# STM32WL3Rx register map
File version: 1.0
Registers are 32-bit, read-write, reset 0x0 unless marked. A register's access mark holds for its fields unless they carry their own. Offsets are from the block's base; [hi:lo] are bit positions; {n}, {i} and the like mark numbered series.

## ADC1 — ADC (ADC)
Base 0x41006000
0x00 VERSION_ID — (@ 0x00000000) VERSION_ID register
  [7:0] VERSION_ID
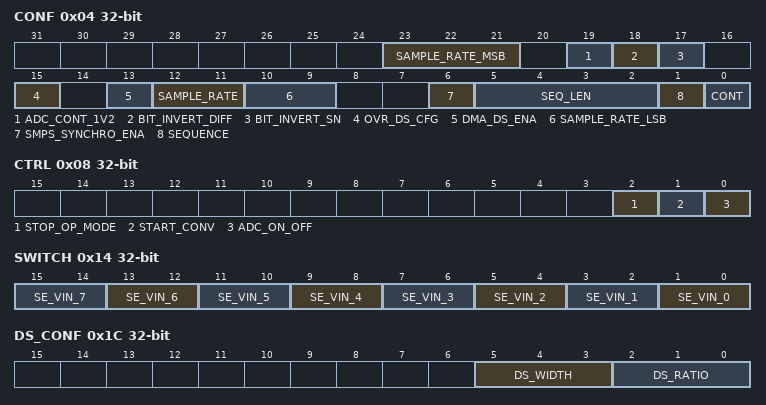
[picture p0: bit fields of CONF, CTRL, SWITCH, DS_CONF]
0x04 CONF — (@ 0x00000004) ADC configuration register
  [23:21] SAMPLE_RATE_MSB
  [19] ADC_CONT_1V2
    0=START; 1=END
  [18] BIT_INVERT_DIFF
  [17] BIT_INVERT_SN
  [15] OVR_DS_CFG
    0=LOST (Previous data is preserved, new data is lost.); 1=KEPT (Previous data is overwritten, new data is kept.)
  [13] DMA_DS_ENA
  [12:11] SAMPLE_RATE
  [10:9] SAMPLE_RATE_LSB
  [6] SMPS_SYNCHRO_ENA
  [5:2] SEQ_LEN
  [1] SEQUENCE
  [0] CONT
0x08 CTRL — (@ 0x00000008) ADC control register
  [2] STOP_OP_MODE, [1] START_CONV, [0] ADC_ON_OFF
0x14 SWITCH — (@ 0x00000014) ADC switch control for Input Selection
  [2n+1:2n] SE_VIN_{n} (n=0..7)
0x1C DS_CONF — (@ 0x0000001C) Downsampler configuration register
  [5:3] DS_WIDTH
  [2:0] DS_RATIO
    0=RATIO_1 (ADC Down Sampler ratio 1, no down sampling (default)); 1=RATIO_2 (ADC Down Sampler ratio 2); 2=RATIO_4 (ADC Down Sampler ratio 4); 3=RATIO_8 (ADC Down Sampler ratio 8); 4=RATIO_16 (ADC Down Sampler ratio 16); 5=RATIO_32 (ADC Down Sampler ratio 32); 6=RATIO_64 (ADC Down Sampler ratio 64); 7=RATIO_128 (ADC Down Sampler ratio 128)
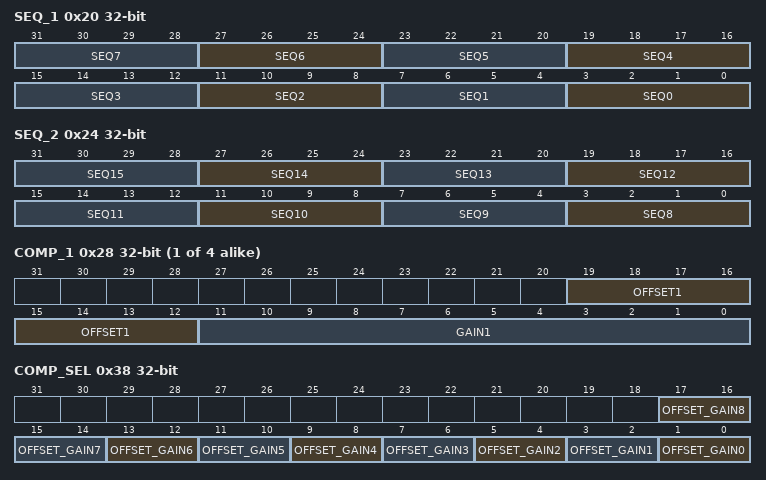
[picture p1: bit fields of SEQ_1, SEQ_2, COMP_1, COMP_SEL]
0x20 SEQ_1 — (@ 0x00000020) ADC regular sequence programming register 1
  [4n+3:4n] SEQ{n} (n=0..7)
0x24 SEQ_2 — (@ 0x00000024) ADC regular sequence programming register 2
  [4n-29:4n-32] SEQ{n} (n=8..15)
{0x24+4i} COMP_{i} (i=1..4) — (@ {0x24+4i}) ADC Gain &
  [19:12] OFFSET{i}, [11:0] GAIN{i}
0x38 COMP_SEL — (@ 0x00000038) ADC Gain &
  [2n+1:2n] OFFSET_GAIN{n} (n=0..8)
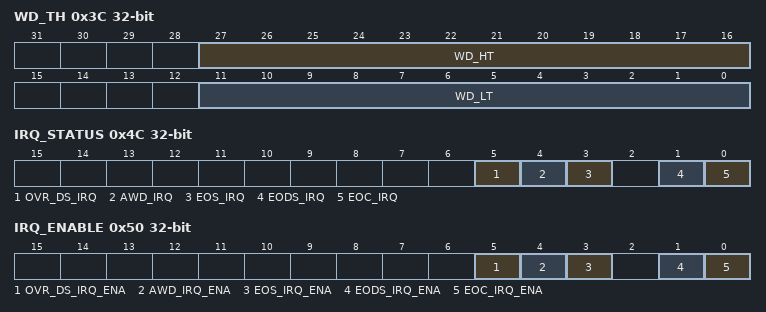
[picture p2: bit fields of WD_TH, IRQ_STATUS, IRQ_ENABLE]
0x3C WD_TH — (@ 0x0000003C) ADC watchdog threshold register register
  [27:16] WD_HT, [11:0] WD_LT
0x40 WD_CONF — (@ 0x00000040) ADC watchdog configuration register
  [15:0] AWD_CHX
    1=VINM0 (ADC watchdog channel selection: VINM0 to negative input); 2=VINM1 (ADC watchdog channel selection: VINM1 to negative input); 4=VINM2 (ADC watchdog channel selection: VINM2 to negative input); 8=VINM3 (ADC watchdog channel selection: VINM3 to negative input); 16=MICROM (ADC watchdog channel selection: MICROM to negative input); 32=VBAT (ADC watchdog channel selection: VBAT to negative input); 64=GND_NEG (ADC watchdog channel selection: GND to negative input); 128=VDDA_NEG (ADC watchdog channel selection: VDDA to negative input); 0x100=VINP0 (ADC watchdog channel selection: VINP0 to positive input); 0x200=VINP1 (ADC watchdog channel selection: VINP1 to positive input); 0x400=VINP2 (ADC watchdog channel selection: VINP2 to positive input); 0x800=VINP3 (ADC watchdog channel selection: VINP3 to positive input); 0x1000=MICROP (ADC watchdog channel selection: MICROP to positive input); 0x2000=TEMPSENSOR (ADC watchdog channel selection: TEMP to positive input); 0x4000=GND_POS (ADC watchdog channel selection: GND to positive input); 0x8000=VDDA_POS (ADC watchdog channel selection: VDDA to positive input)
0x44 DS_DATAOUT — (@ 0x00000044) Downsampler Data output register
  [15:0] DS_DATA
0x4C IRQ_STATUS — (@ 0x0000004C) Interrupt Status register
  [5] OVR_DS_IRQ, [4] AWD_IRQ, [3] EOS_IRQ, [1] EODS_IRQ, [0] EOC_IRQ
0x50 IRQ_ENABLE — (@ 0x00000050) Enable/disable Interrupts
  [5] OVR_DS_IRQ_ENA, [4] AWD_IRQ_ENA, [3] EOS_IRQ_ENA, [1] EODS_IRQ_ENA, [0] EOC_IRQ_ENA

## SPI3 — Serial peripheral interface/Inter-IC sound (SPI)
Base 0x41007000
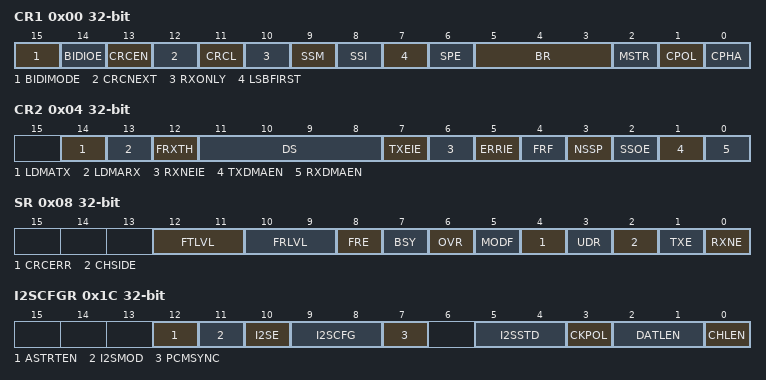
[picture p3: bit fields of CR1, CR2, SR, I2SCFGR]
0x00 CR1 — (@ 0x00000000) Control register 1
  [15] BIDIMODE
  [14] BIDIOE
  [13] CRCEN
  [12] CRCNEXT
  [11] CRCL
    0=CRC_8BIT (8-bit CRC length); 1=CRC_16BIT (16-bit CRC length)
  [10] RXONLY
  [9] SSM
  [8] SSI
  [7] LSBFIRST
    1=LSB_FIRST (Data is transmitted/received with the LSB first); 0=MSB_FIRST (Data is transmitted/received with the MSB first)
  [6] SPE
  [5:3] BR
    0=DIV2 (BaudRate control equal to fPCLK/2); 1=DIV4 (BaudRate control equal to fPCLK/4); 2=DIV8 (BaudRate control equal to fPCLK/8); 3=DIV16 (BaudRate control equal to fPCLK/16); 4=DIV32 (BaudRate control equal to fPCLK/32); 5=DIV64 (BaudRate control equal to fPCLK/64); 6=DIV128 (BaudRate control equal to fPCLK/128); 7=DIV256 (BaudRate control equal to fPCLK/256)
  [2] MSTR
  [1] CPOL
    0=LOW (Clock to 0 when idle); 1=HIGH (Clock to 1 when idle)
  [0] CPHA
    0=PHASE_1EDGE (First clock transition is the first data capture edge); 1=PHASE_2EDGE (Second clock transition is the first data capture edge)
0x04 CR2 — (@ 0x00000004) Control register 2
  [14] LDMATX
  [13] LDMARX
  [12] FRXTH
    0=HALF (RXNE event is generated if FIFO level is greater than or equal to 1/2 (16-bit)); 1=QUARTER (RXNE event is generated if FIFO level is greater than or equal to 1/4 (8-bit))
  [11:8] DS
    {v}=DATAWIDTH_{v+1}BIT (Data length for SPI transfer: {v+1} bits) (v=3..15)
  [7] TXEIE
  [6] RXNEIE
  [5] ERRIE
  [4] FRF
    0=MOTOROLA (Motorola mode. Used as default value); 1=TI (TI mode)
  [3] NSSP
  [2] SSOE
  [1] TXDMAEN
  [0] RXDMAEN
0x08 SR — (@ 0x00000008) Status register
  [12:11] FTLVL
    0=EMPTY (FIFO transmission empty); 1=QUARTER_FULL (FIFO transmission 1/4); 2=HALF_FULL (FIFO transmission 1/2); 3=FULL (FIFO transmission full)
  [10:9] FRLVL
    0=EMPTY (FIFO reception empty); 1=QUARTER_FULL (FIFO reception 1/4); 2=HALF_FULL (FIFO reception 1/2); 3=FULL (FIFO reception full)
  [8] FRE
  [7] BSY
  [6] OVR
  [5] MODF
  [4] CRCERR
  [3] UDR
  [2] CHSIDE
  [1] TXE
  [0] RXNE
0x0C DR — (@ 0x0000000C) Data register
  [15:0] DR
0x10 CRCPR — (@ 0x00000010) CRC polynomial register
  [15:0] CRCPOLY
0x14 RXCRCR — (@ 0x00000014) RX CRC register
  [15:0] RXCRC
0x18 TXCRCR — (@ 0x00000018) TX CRC register
  [15:0] TXCRC
0x1C I2SCFGR — (@ 0x0000001C) I2S configuration register
  [12] ASTRTEN
  [11] I2SMOD
  [10] I2SE
  [9:8] I2SCFG
    0=SLAVE_TX (Slave Tx configuration); 1=SLAVE_RX (Slave Rx configuration); 2=MASTER_TX (Master Tx configuration); 3=MASTER_RX (Master Rx configuration)
  [7] PCMSYNC
  [5:4] I2SSTD
  [3] CKPOL
    0=LOW (Clock steady state is low level); 1=HIGH (Clock steady state is high level)
  [2:1] DATLEN
  [0] CHLEN
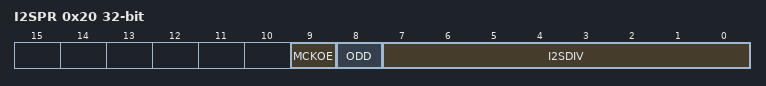
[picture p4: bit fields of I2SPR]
0x20 I2SPR — (@ 0x00000020) I2S prescaler register
  [9] MCKOE, [8] ODD, [7:0] I2SDIV
